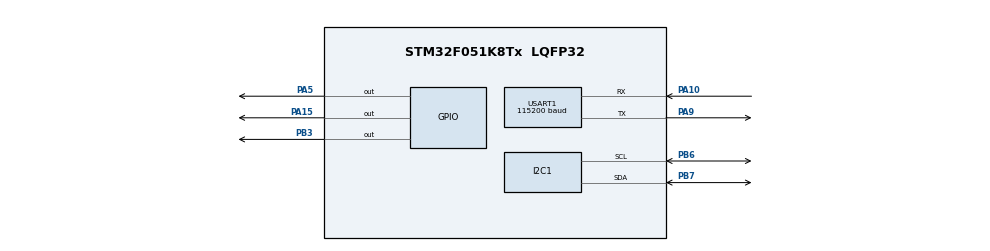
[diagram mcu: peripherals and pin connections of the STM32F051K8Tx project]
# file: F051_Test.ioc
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Dma.Request0=USART1_RX
Dma.USART1_RX.0.Direction=DMA_PERIPH_TO_MEMORY
Dma.USART1_RX.0.Instance=DMA1_Channel3
Dma.USART1_RX.0.MemDataAlignment=DMA_MDATAALIGN_BYTE
Dma.USART1_RX.0.MemInc=DMA_MINC_ENABLE
Dma.USART1_RX.0.Mode=DMA_CIRCULAR
Dma.USART1_RX.0.PeriphDataAlignment=DMA_PDATAALIGN_BYTE
Dma.USART1_RX.0.PeriphInc=DMA_PINC_DISABLE
Dma.USART1_RX.0.Priority=DMA_PRIORITY_LOW
Mcu.Family=STM32F0
Mcu.Name=STM32F051K8Tx
Mcu.Package=LQFP32
NVIC.DMA1_Channel2_3_IRQn=true\:0\:0\:false\:false\:true\:false\:true
NVIC.USART1_IRQn=true\:0\:0\:false\:false\:true\:true\:true
PA10.Mode=Asynchronous
PA10.Signal=USART1_RX
PA15.Signal=GPIO_Output
PA5.Signal=GPIO_Output
PA9.Mode=Asynchronous
PA9.Signal=USART1_TX
PB3.Signal=GPIO_Output
PB6.Mode=I2C
PB6.Signal=I2C1_SCL
PB7.Mode=I2C
PB7.Signal=I2C1_SDA
ProjectManager.HeapSize=0x200
ProjectManager.StackSize=0x400
ProjectManager.TargetToolchain=STM32CubeIDE
USART1.BaudRate=115200
USART1.VirtualMode-Asynchronous=VM_ASYNC
board=custom

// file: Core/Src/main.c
/* USER CODE BEGIN Header */
/**
  ******************************************************************************
  * @file           : main.c
  * @brief          : Main program body
  ******************************************************************************
  * @attention
  *
  * <h2><center>&copy; Copyright (c) 2020 STMicroelectronics.
  * All rights reserved.</center></h2>
  *
  * This software component is licensed by ST under BSD 3-Clause license,
  * the "License"; You may not use this file except in compliance with the
  * License. You may obtain a copy of the License at:
  *                        opensource.org/licenses/BSD-3-Clause
  *
  ******************************************************************************
  */
/* USER CODE END Header */
#include "main.h"
#include "dma.h"
#include "i2c.h"
#include "usart.h"
#include "gpio.h"

/* USER CODE BEGIN Includes */

#include "user_app.h"
/* USER CODE END Includes */

void SystemClock_Config(void);

/* USER CODE BEGIN 0 */

/*
 * 	@brief scan for i2c device
 */

/*
 * @brief receive UART data via callback
 */

/* USER CODE END 0 */

int main(void)
{

  /* MCU Configuration--------------------------------------------------------*/

  /* Reset of all peripherals, Initializes the Flash interface and the Systick. */
  HAL_Init();

  /* Configure the system clock */
  SystemClock_Config();

  /* Initialize all configured peripherals */
  MX_GPIO_Init();
  MX_DMA_Init();
  MX_USART1_UART_Init();
  MX_I2C1_Init();
  /* USER CODE BEGIN 2 */

  test_i2c_device();

  // start receiving on UART via DMA

  HAL_UART_Receive_DMA(&huart1, uart_data_in, 1);

  /* USER CODE END 2 */

  /* Infinite loop */
  /* USER CODE BEGIN WHILE */
  while (1)
  {
	  i2c_display_loop();

	  HAL_GPIO_TogglePin(GPIOA, GPIO_PIN_5);
	  HAL_Delay(1000);
    /* USER CODE END WHILE */

  }
}

void SystemClock_Config(void)
{
  RCC_OscInitTypeDef RCC_OscInitStruct = {0};
  RCC_ClkInitTypeDef RCC_ClkInitStruct = {0};
  RCC_PeriphCLKInitTypeDef PeriphClkInit = {0};

  /** Initializes the RCC Oscillators according to the specified parameters
  * in the RCC_OscInitTypeDef structure.
  */
  RCC_OscInitStruct.OscillatorType = RCC_OSCILLATORTYPE_HSI;
  RCC_OscInitStruct.HSIState = RCC_HSI_ON;
  RCC_OscInitStruct.HSICalibrationValue = RCC_HSICALIBRATION_DEFAULT;
  RCC_OscInitStruct.PLL.PLLState = RCC_PLL_NONE;
  if (HAL_RCC_OscConfig(&RCC_OscInitStruct) != HAL_OK)
  {
    Error_Handler();
  }
  /** Initializes the CPU, AHB and APB buses clocks
  */
  RCC_ClkInitStruct.ClockType = RCC_CLOCKTYPE_HCLK|RCC_CLOCKTYPE_SYSCLK
                              |RCC_CLOCKTYPE_PCLK1;
  RCC_ClkInitStruct.SYSCLKSource = RCC_SYSCLKSOURCE_HSI;
  RCC_ClkInitStruct.AHBCLKDivider = RCC_SYSCLK_DIV1;
  RCC_ClkInitStruct.APB1CLKDivider = RCC_HCLK_DIV1;

  if (HAL_RCC_ClockConfig(&RCC_ClkInitStruct, FLASH_LATENCY_0) != HAL_OK)
  {
    Error_Handler();
  }
  PeriphClkInit.PeriphClockSelection = RCC_PERIPHCLK_USART1|RCC_PERIPHCLK_I2C1;
  PeriphClkInit.Usart1ClockSelection = RCC_USART1CLKSOURCE_PCLK1;
  PeriphClkInit.I2c1ClockSelection = RCC_I2C1CLKSOURCE_HSI;
  if (HAL_RCCEx_PeriphCLKConfig(&PeriphClkInit) != HAL_OK)
  {
    Error_Handler();
  }
}

void Error_Handler(void)
{
}

/************************ (C) COPYRIGHT STMicroelectronics *****END OF FILE****/
